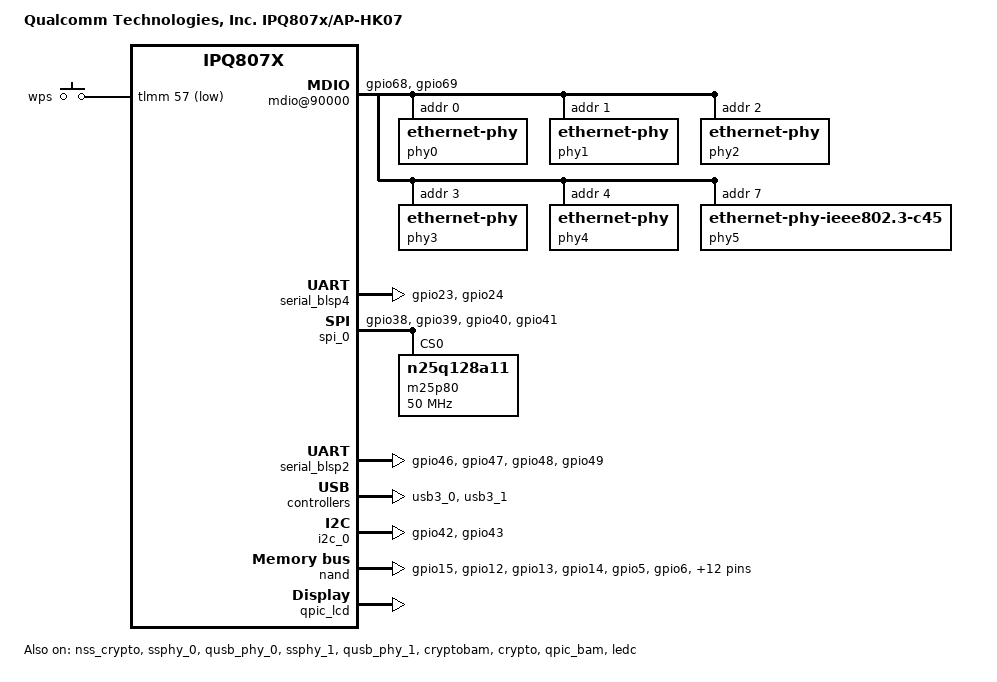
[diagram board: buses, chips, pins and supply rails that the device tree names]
/dts-v1/;
/*
 * Copyright (c) 2017-2018, The Linux Foundation. All rights reserved.
 *
 * Permission to use, copy, modify, and/or distribute this software for any
 * purpose with or without fee is hereby granted, provided that the above
 * copyright notice and this permission notice appear in all copies.
 *
 * THE SOFTWARE IS PROVIDED "AS IS" AND THE AUTHOR DISCLAIMS ALL WARRANTIES
 * WITH REGARD TO THIS SOFTWARE INCLUDING ALL IMPLIED WARRANTIES OF
 * MERCHANTABILITY AND FITNESS. IN NO EVENT SHALL THE AUTHOR BE LIABLE FOR
 * ANY SPECIAL, DIRECT, INDIRECT, OR CONSEQUENTIAL DAMAGES OR ANY DAMAGES
 * WHATSOEVER RESULTING FROM LOSS OF USE, DATA OR PROFITS, WHETHER IN AN
 * ACTION OF CONTRACT, NEGLIGENCE OR OTHER TORTIOUS ACTION, ARISING OUT OF
 * OR IN CONNECTION WITH THE USE OR PERFORMANCE OF THIS SOFTWARE.
 */
#include "qcom-ipq807x-soc.dtsi"
#include "qcom-ipq807x-audio.dtsi"

/ {
	#address-cells = <0x2>;
	#size-cells = <0x2>;
	model = "Qualcomm Technologies, Inc. IPQ807x/AP-HK07";
	compatible = "qcom,ipq807x-hk07", "qcom,ipq807x";
	qcom,msm-id = <0x125 0x0>;
	interrupt-parent = <&intc>;
	qcom,board-id = <0x10 0x0>;

	aliases {
		/*
		 * Aliases as required by u-boot
		 * to patch MAC addresses
		 */
		ethernet0 = "/soc/dp1";
		ethernet1 = "/soc/dp2";
		ethernet2 = "/soc/dp3";
		ethernet3 = "/soc/dp4";
		ethernet4 = "/soc/dp5";
		ethernet5 = "/soc/dp6";
	};

	chosen {
		bootargs = "console=ttyMSM0,115200,n8 root=/dev/ram0 rw \
			init=/init";
		bootargs-append = " swiotlb=1";
	};
};

&tlmm {
	pinctrl-0 = <&btcoex_pins>;
	pinctrl-names = "default";

	btcoex_pins: btcoex_pins {
		mux_0 {
			pins = "gpio64";
			function = "pta1_1";
			drive-strength = <6>;
			bias-pull-down;
		};
		mux_1 {
			pins = "gpio65";
			function = "pta1_2";
			drive-strength = <6>;
			bias-pull-down;
		};
		mux_2 {
			pins = "gpio66";
			function = "pta1_0";
			drive-strength = <6>;
			bias-pull-down;
		};
		mux_3 {
			pins = "gpio54";
			function = "pta2_0";
			drive-strength = <6>;
			bias-pull-down;
		};
		mux_4 {
			pins = "gpio55";
			function = "pta2_1";
			drive-strength = <6>;
			bias-pull-down;
		};
		mux_5 {
			pins = "gpio56";
			function = "pta2_2";
			drive-strength = <6>;
			bias-pull-down;
		};
	};

	mdio_pins: mdio_pinmux {
		mux_0 {
			pins = "gpio68";
			function = "mdc";
			drive-strength = <8>;
			bias-pull-up;
		};
		mux_1 {
			pins = "gpio69";
			function = "mdio";
			drive-strength = <8>;
			bias-pull-up;
		};
	};

	uart_pins: uart_pins {
		mux {
			pins = "gpio23", "gpio24";
			function = "blsp4_uart1";
			drive-strength = <8>;
			bias-disable;
		};
	};

	i2c_0_pins: i2c_0_pinmux {
		mux {
			pins = "gpio42", "gpio43";
			function = "blsp1_i2c";
			drive-strength = <8>;
			bias-disable;
		};
	};

	spi_0_pins: spi_0_pins {
		mux {
			pins = "gpio38", "gpio39", "gpio40", "gpio41";
			function = "blsp0_spi";
			drive-strength = <8>;
			bias-disable;
		};
	};

	qpic_pins: qpic_pins {
		data_0 {
			pins = "gpio15";
			function = "qpic_pad0";
			drive-strength = <8>;
			bias-disable;
		};
		data_1 {
			pins = "gpio12";
			function = "qpic_pad1";
			drive-strength = <8>;
			bias-disable;
		};
		data_2 {
			pins = "gpio13";
			function = "qpic_pad2";
			drive-strength = <8>;
			bias-disable;
		};
		data_3 {
			pins = "gpio14";
			function = "qpic_pad3";
			drive-strength = <8>;
			bias-disable;
		};
		data_4 {
			pins = "gpio5";
			function = "qpic_pad4";
			drive-strength = <8>;
			bias-disable;
		};
		data_5 {
			pins = "gpio6";
			function = "qpic_pad5";
			drive-strength = <8>;
			bias-disable;
		};
		data_6 {
			pins = "gpio7";
			function = "qpic_pad6";
			drive-strength = <8>;
			bias-disable;
		};
		data_7 {
			pins = "gpio8";
			function = "qpic_pad7";
			drive-strength = <8>;
			bias-disable;
		};
		data_8 {
			pins = "gpio16";
			function = "qpic_pad8";
			drive-strength = <8>;
			bias-disable;
		};
		qpic_pad {
			pins = "gpio0", "gpio1", "gpio2", "gpio3", "gpio4",
			       "gpio9", "gpio10", "gpio11", "gpio17";
			function = "qpic_pad";
			drive-strength = <8>;
			bias-disable;
		};
	};

	sd_pins: sd_pins {
		mux {
			pins = "gpio63";
			function = "sd_card";
			drive-strength = <8>;
			bias-pull-up;
		};
	};

	hsuart_pins: hsuart_pins {
		mux {
			pins = "gpio46", "gpio47", "gpio48", "gpio49";
			function = "blsp2_uart";
			drive-strength = <8>;
			bias-disable;
		};
	};

	ledc_pins: ledc_pinmux {
		led_clk {
			pins = "gpio18";
			function = "led0";
			drive-strength = <8>;
			bias-pull-down;
		};
		led_data {
			pins = "gpio19";
			function = "led1";
			drive-strength = <8>;
			bias-pull-down;
		};
		led_clr {
			pins = "gpio20";
			function = "led2";
			drive-strength = <8>;
			bias-pull-up;
		};
	};

	button_pins: button_pins {
		wps_button {
			pins = "gpio57";
			function = "gpio";
			drive-strength = <8>;
			bias-pull-up;
		};
	};

	uniphy_pins: uniphy_pinmux {
		mux {
			pins = "gpio60";
			function = "rx2";
			bias-disable;
		};

		sfp_tx {
			pins = "gpio59";
			function = "gpio";
			drive-strength = <8>;
			bias-pull-down;
			output-low;
		};
	};

	pwm_pins: pwm_pinmux {
		mux_1 {
			pins = "gpio25";
			function = "pwm02";
			drive-strength = <8>;
		};
	};
};

&soc {
	pwm {
		pinctrl-0 = <&pwm_pins>;
		pinctrl-names = "default";
		used-pwm-indices = <1>, <0>, <0>, <0>;
		status = "disabled";
	};

	gpio_keys {
		compatible = "gpio-keys";
		pinctrl-0 = <&button_pins>;
		pinctrl-names = "default";

		button@1 {
			label = "wps";
			linux,code = <KEY_WPS_BUTTON>;
			gpios = <&tlmm 57 GPIO_ACTIVE_LOW>;
			linux,input-type = <1>;
			debounce-interval = <60>;
		};
	};

	mdio@90000 {
		pinctrl-0 = <&mdio_pins>;
		pinctrl-names = "default";
		phy-reset-gpio = <&tlmm 37 0>;
		phy0: ethernet-phy@0 {
			reg = <0>;
		};
		phy1: ethernet-phy@1 {
			reg = <1>;
		};
		phy2: ethernet-phy@2 {
			reg = <2>;
		};
		phy3: ethernet-phy@3 {
			reg = <3>;
		};
		phy4: ethernet-phy@4 {
			reg = <4>;
		};
		phy5: ethernet-phy@5 {
			compatible ="ethernet-phy-ieee802.3-c45";
			reg = <7>;
		};
	};

};

&serial_blsp4 {
	pinctrl-0 = <&uart_pins>;
	pinctrl-names = "default";
	status = "ok";
};

&spi_0 { /* BLSP1 QUP1 */
	pinctrl-0 = <&spi_0_pins>;
	pinctrl-names = "default";
	status = "ok";

	m25p80@0 {
		#address-cells = <1>;
		#size-cells = <1>;
		reg = <0>;
		compatible = "n25q128a11";
		linux,modalias = "m25p80", "n25q128a11";
		spi-max-frequency = <50000000>;
		use-default-sizes;
	};
};

&serial_blsp2 {
	pinctrl-0 = <&hsuart_pins>;
	pinctrl-names = "default";
	status = "ok";
};

&nss_crypto {
	status = "ok";
};

&msm_imem {
	status = "disabled";
};

&ssphy_0 {
	qcom,emulation = <1>;
	status = "ok";
};

&qusb_phy_0 {
	qcom,emulation = <1>;
	status = "ok";
};

&ssphy_1 {
	qcom,emulation = <1>;
	status = "ok";
};

&qusb_phy_1 {
	qcom,emulation = <1>;
	status = "ok";
};

&usb3_0 {
	status = "ok";
};

&usb3_1 {
	status = "ok";
};

&cryptobam {
	status = "ok";
};

&crypto {
	status = "ok";
};

&i2c_0 {
	pinctrl-0 = <&i2c_0_pins>;
	pinctrl-names = "default";
	status = "ok";
};

&i2c_1 {
	status = "disabled";
};

&qpic_bam {
	status = "ok";
};

&nand {
	pinctrl-0 = <&qpic_pins>;
	pinctrl-names = "default";
	status = "ok";
};

&qpic_lcd {
	status = "ok";
};

&qpic_lcd_panel {
	status = "ok";
};

&ledc {
	pinctrl-0 = <&ledc_pins>;
	pinctrl-names = "default";
	status = "ok";
};
